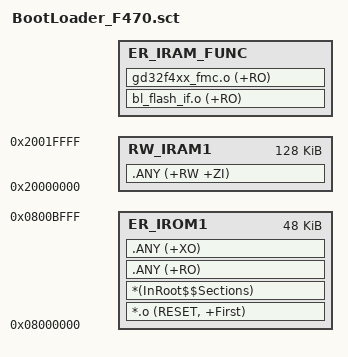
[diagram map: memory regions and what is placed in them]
; BootLoader scatter file for GD32F470VET6
; FLASH: 0x08000000 - 0x0807FFFF (512KB)
; BOOT : 0x08000000 - 0x0800BFFF (48KB)

LR_IROM1 0x08000000 0x0000C000  {
  ER_IROM1 0x08000000 0x0000C000  {
   *.o (RESET, +First)
   *(InRoot$$Sections)
   .ANY (+RO)
   .ANY (+XO)
  }
  RW_IRAM1 0x20000000 0x00020000  {
   .ANY (+RW +ZI)
  }
  ER_IRAM_FUNC +0  {
   bl_flash_if.o (+RO)
   gd32f4xx_fmc.o (+RO)
  }
}
